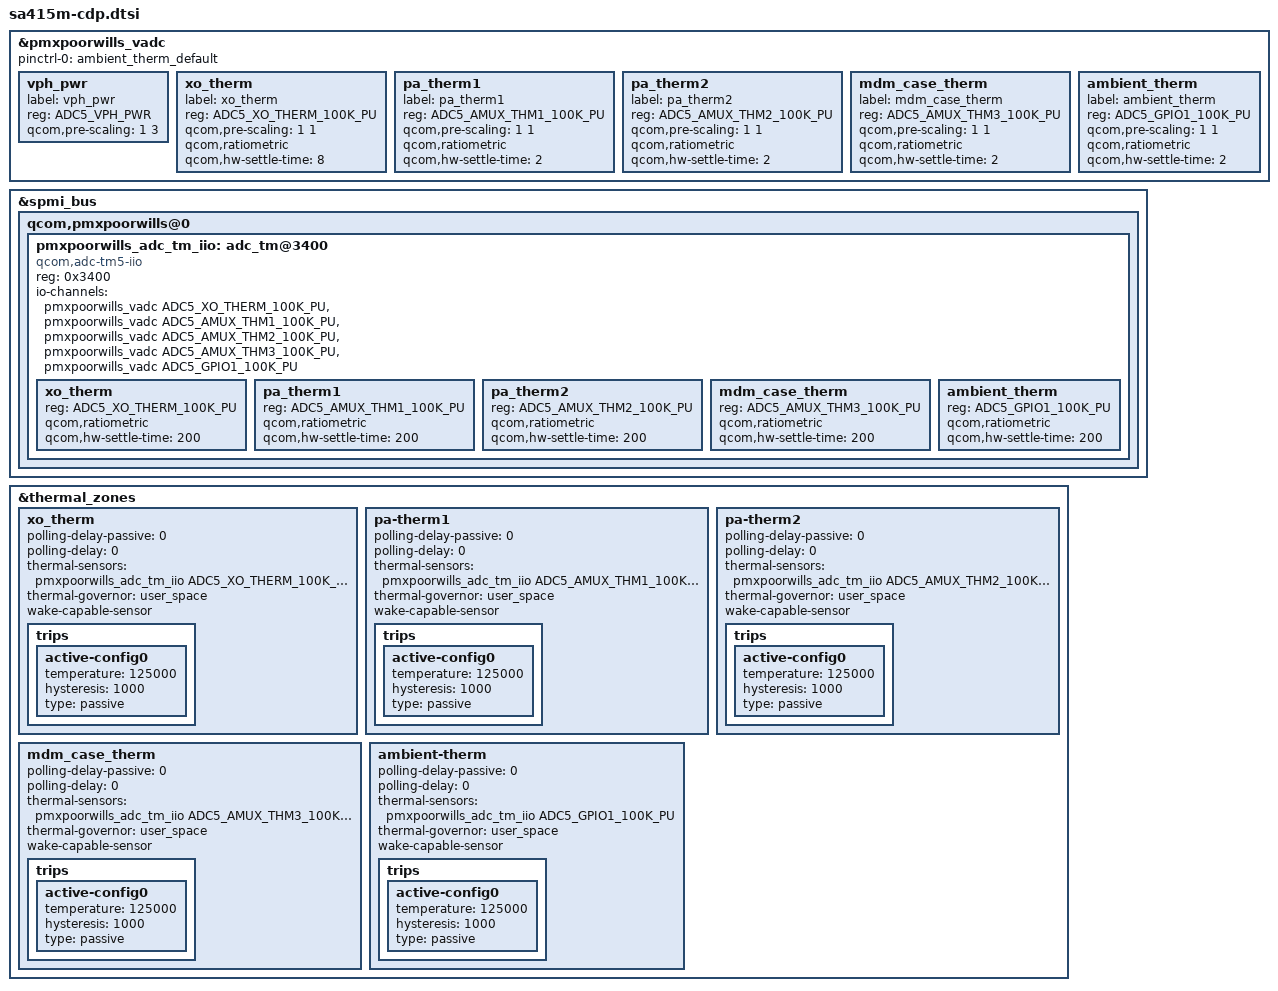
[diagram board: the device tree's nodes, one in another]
#include "sa415m.dtsi"
#include "sa415m-pinctrl.dtsi"
#include "sa415m-cdp-audio-overlay.dtsi"

&pmxpoorwills_vadc {
	pinctrl-names = "default";
	pinctrl-0 = <&ambient_therm_default>;

	vph_pwr {
		label = "vph_pwr";
		reg = <ADC5_VPH_PWR>;
		qcom,pre-scaling = <1 3>;
	};

	xo_therm {
		label = "xo_therm";
		reg = <ADC5_XO_THERM_100K_PU>;
		qcom,pre-scaling = <1 1>;
		qcom,ratiometric;
		qcom,hw-settle-time = <8>;
	};

	pa_therm1 {
		label = "pa_therm1";
		reg = <ADC5_AMUX_THM1_100K_PU>;
		qcom,pre-scaling = <1 1>;
		qcom,ratiometric;
		qcom,hw-settle-time = <2>;
	};

	pa_therm2 {
		label = "pa_therm2";
		reg = <ADC5_AMUX_THM2_100K_PU>;
		qcom,pre-scaling = <1 1>;
		qcom,ratiometric;
		qcom,hw-settle-time = <2>;
	};

	mdm_case_therm {
		label = "mdm_case_therm";
		reg = <ADC5_AMUX_THM3_100K_PU>;
		qcom,pre-scaling = <1 1>;
		qcom,ratiometric;
		qcom,hw-settle-time = <2>;
	};

	ambient_therm {
		label = "ambient_therm";
		reg = <ADC5_GPIO1_100K_PU>;
		qcom,pre-scaling = <1 1>;
		qcom,ratiometric;
		qcom,hw-settle-time = <2>;
	};
};

&spmi_bus {
	qcom,pmxpoorwills@0 {
		pmxpoorwills_adc_tm_iio: adc_tm@3400 {
			compatible = "qcom,adc-tm5-iio";
			reg = <0x3400>;
			#thermal-sensor-cells = <1>;
			#address-cells = <1>;
			#size-cells = <0>;
			io-channels =   <&pmxpoorwills_vadc ADC5_XO_THERM_100K_PU>,
					<&pmxpoorwills_vadc ADC5_AMUX_THM1_100K_PU>,
					<&pmxpoorwills_vadc ADC5_AMUX_THM2_100K_PU>,
					<&pmxpoorwills_vadc ADC5_AMUX_THM3_100K_PU>,
					<&pmxpoorwills_vadc ADC5_GPIO1_100K_PU>;

			xo_therm {
				reg = <ADC5_XO_THERM_100K_PU>;
				qcom,ratiometric;
				qcom,hw-settle-time = <200>;
			};

			pa_therm1 {
				reg = <ADC5_AMUX_THM1_100K_PU>;
				qcom,ratiometric;
				qcom,hw-settle-time = <200>;
			};

			pa_therm2 {
				reg = <ADC5_AMUX_THM2_100K_PU>;
				qcom,ratiometric;
				qcom,hw-settle-time = <200>;
			};

			mdm_case_therm {
				reg = <ADC5_AMUX_THM3_100K_PU>;
				qcom,ratiometric;
				qcom,hw-settle-time = <200>;
			};

			ambient_therm {
				reg = <ADC5_GPIO1_100K_PU>;
				qcom,ratiometric;
				qcom,hw-settle-time = <200>;
			};
		};
	};
};

&thermal_zones {
	xo_therm {
		polling-delay-passive = <0>;
		polling-delay = <0>;
		thermal-sensors = <&pmxpoorwills_adc_tm_iio ADC5_XO_THERM_100K_PU>;
		thermal-governor = "user_space";
		wake-capable-sensor;

		trips {
			active-config0 {
				temperature = <125000>;
				hysteresis = <1000>;
				type = "passive";
			};
		};
	};

	pa-therm1 {
		polling-delay-passive = <0>;
		polling-delay = <0>;
		thermal-sensors = <&pmxpoorwills_adc_tm_iio ADC5_AMUX_THM1_100K_PU>;
		thermal-governor = "user_space";
		wake-capable-sensor;

		trips {
			active-config0 {
				temperature = <125000>;
				hysteresis = <1000>;
				type = "passive";
			};
		};
	};

	pa-therm2 {
		polling-delay-passive = <0>;
		polling-delay = <0>;
		thermal-sensors = <&pmxpoorwills_adc_tm_iio ADC5_AMUX_THM2_100K_PU>;
		thermal-governor = "user_space";
		wake-capable-sensor;

		trips {
			active-config0 {
				temperature = <125000>;
				hysteresis = <1000>;
				type = "passive";
			};
		};
	};

	mdm_case_therm {
		polling-delay-passive = <0>;
		polling-delay = <0>;
		thermal-sensors = <&pmxpoorwills_adc_tm_iio ADC5_AMUX_THM3_100K_PU>;
		thermal-governor = "user_space";
		wake-capable-sensor;

		trips {
			active-config0 {
				temperature = <125000>;
				hysteresis = <1000>;
				type = "passive";
			};
		};
	};

	ambient-therm {
		polling-delay-passive = <0>;
		polling-delay = <0>;
		thermal-sensors = <&pmxpoorwills_adc_tm_iio ADC5_GPIO1_100K_PU>;
		thermal-governor = "user_space";
		wake-capable-sensor;

		trips {
			active-config0 {
				temperature = <125000>;
				hysteresis = <1000>;
				type = "passive";
			};
		};
	};
};
